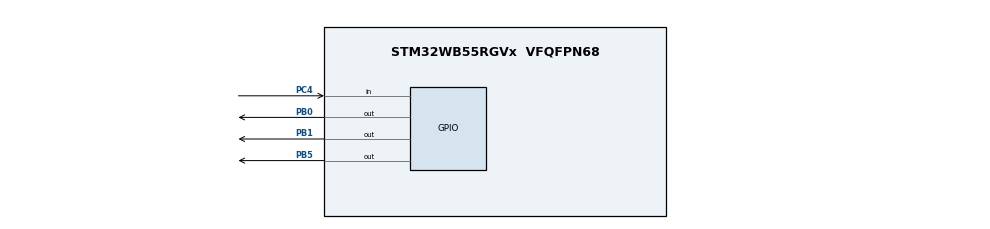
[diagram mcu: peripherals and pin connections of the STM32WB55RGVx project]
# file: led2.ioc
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Mcu.Family=STM32WB
Mcu.Name=STM32WB55RGVx
Mcu.Package=VFQFPN68
NVIC.PriorityGroup=NVIC_PRIORITYGROUP_4
PB0.Signal=GPIO_Output
PB1.Signal=GPIO_Output
PB5.Signal=GPIO_Output
PC4.GPIO_PuPd=GPIO_PULLUP
PC4.Signal=GPIO_Input
ProjectManager.HeapSize=0x200
ProjectManager.StackSize=0x400
ProjectManager.TargetToolchain=STM32CubeIDE
RCC.APB3Freq_Value=16000000
RCC.HSE_VALUE=8000000
RCC.HSI48_VALUE=48000000
RCC.HSI_VALUE=16000000
RCC.LSE_VALUE=32768
RCC.VCOOutputFreq_Value=32000000
board=custom

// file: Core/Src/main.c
/* USER CODE BEGIN Header */
/**
  ******************************************************************************
  * @file           : main.c
  * @brief          : Main program body
  ******************************************************************************
  * @attention
  *
  * Copyright (c) 2025 STMicroelectronics.
  * All rights reserved.
  *
  * This software is licensed under terms that can be found in the LICENSE file
  * in the root directory of this software component.
  * If no LICENSE file comes with this software, it is provided AS-IS.
  *
  ******************************************************************************
  */
/* USER CODE END Header */
#include "main.h"
#include "gpio.h"

void SystemClock_Config(void);
void PeriphCommonClock_Config(void);

int main(void)
{

  /* MCU Configuration--------------------------------------------------------*/

  /* Reset of all peripherals, Initializes the Flash interface and the Systick. */
  HAL_Init();

  /* Configure the system clock */
  SystemClock_Config();

  /* Configure the peripherals common clocks */
  PeriphCommonClock_Config();

  /* Initialize all configured peripherals */
  MX_GPIO_Init();
  /* USER CODE BEGIN 2 */

  uint8_t press_count = 0;
  uint8_t prev_button_state = 1;  // 1 = not pressed, 0 = pressed
  /* USER CODE END 2 */

  /* Infinite loop */
  while (1)
  {
	  uint8_t current_state = HAL_GPIO_ReadPin(GPIOC, GPIO_PIN_4);

	 	      // Detect rising edge: button was released before and now pressed
	 	      if (prev_button_state == 1 && current_state == 0)
	 	      {
	 	          press_count++;
	 	          if (press_count > 3) press_count = 1;

	 	          // Turn off all LEDs first
	 	          HAL_GPIO_WritePin(GPIOB, GPIO_PIN_5, GPIO_PIN_RESET);
	 	          HAL_GPIO_WritePin(GPIOB, GPIO_PIN_1, GPIO_PIN_RESET);
	 	          HAL_GPIO_WritePin(GPIOB, GPIO_PIN_0, GPIO_PIN_RESET);

	 	          // Turn ON the corresponding LED
	 	          switch (press_count)
	 	          {
	 	              case 1 :
	 	                  HAL_GPIO_WritePin(GPIOB, GPIO_PIN_1, GPIO_PIN_SET);  // LED1
	 	                  break;
	 	              case 2:
	 	                  HAL_GPIO_WritePin(GPIOB, GPIO_PIN_5, GPIO_PIN_SET);  // LED2
	 	                  break;
	 	              case 3:
	 	                  HAL_GPIO_WritePin(GPIOB, GPIO_PIN_0, GPIO_PIN_SET);  // LED3
	 	                  break;
	 	          }

	 	          HAL_Delay(200);  // Simple debounce delay
	 	      }

	 	      prev_button_state = current_state;
  }
}

void SystemClock_Config(void)
{
  RCC_OscInitTypeDef RCC_OscInitStruct = {0};
  RCC_ClkInitTypeDef RCC_ClkInitStruct = {0};

  /** Configure the main internal regulator output voltage
  */
  __HAL_PWR_VOLTAGESCALING_CONFIG(PWR_REGULATOR_VOLTAGE_SCALE1);

  /** Initializes the RCC Oscillators according to the specified parameters
  * in the RCC_OscInitTypeDef structure.
  */
  RCC_OscInitStruct.OscillatorType = RCC_OSCILLATORTYPE_HSI|RCC_OSCILLATORTYPE_MSI;
  RCC_OscInitStruct.HSIState = RCC_HSI_ON;
  RCC_OscInitStruct.MSIState = RCC_MSI_ON;
  RCC_OscInitStruct.HSICalibrationValue = RCC_HSICALIBRATION_DEFAULT;
  RCC_OscInitStruct.MSICalibrationValue = RCC_MSICALIBRATION_DEFAULT;
  RCC_OscInitStruct.MSIClockRange = RCC_MSIRANGE_6;
  RCC_OscInitStruct.PLL.PLLState = RCC_PLL_NONE;
  if (HAL_RCC_OscConfig(&RCC_OscInitStruct) != HAL_OK)
  {
    Error_Handler();
  }

  /** Configure the SYSCLKSource, HCLK, PCLK1 and PCLK2 clocks dividers
  */
  RCC_ClkInitStruct.ClockType = RCC_CLOCKTYPE_HCLK4|RCC_CLOCKTYPE_HCLK2
                              |RCC_CLOCKTYPE_HCLK|RCC_CLOCKTYPE_SYSCLK
                              |RCC_CLOCKTYPE_PCLK1|RCC_CLOCKTYPE_PCLK2;
  RCC_ClkInitStruct.SYSCLKSource = RCC_SYSCLKSOURCE_MSI;
  RCC_ClkInitStruct.AHBCLKDivider = RCC_SYSCLK_DIV1;
  RCC_ClkInitStruct.APB1CLKDivider = RCC_HCLK_DIV1;
  RCC_ClkInitStruct.APB2CLKDivider = RCC_HCLK_DIV1;
  RCC_ClkInitStruct.AHBCLK2Divider = RCC_SYSCLK_DIV1;
  RCC_ClkInitStruct.AHBCLK4Divider = RCC_SYSCLK_DIV1;

  if (HAL_RCC_ClockConfig(&RCC_ClkInitStruct, FLASH_LATENCY_0) != HAL_OK)
  {
    Error_Handler();
  }
}

void PeriphCommonClock_Config(void)
{
  RCC_PeriphCLKInitTypeDef PeriphClkInitStruct = {0};

  /** Initializes the peripherals clock
  */
  PeriphClkInitStruct.PeriphClockSelection = RCC_PERIPHCLK_SMPS;
  PeriphClkInitStruct.SmpsClockSelection = RCC_SMPSCLKSOURCE_HSI;
  PeriphClkInitStruct.SmpsDivSelection = RCC_SMPSCLKDIV_RANGE1;

  if (HAL_RCCEx_PeriphCLKConfig(&PeriphClkInitStruct) != HAL_OK)
  {
    Error_Handler();
  }
}

void Error_Handler(void)
{
  __disable_irq();
  while (1)
  {
  }
}
